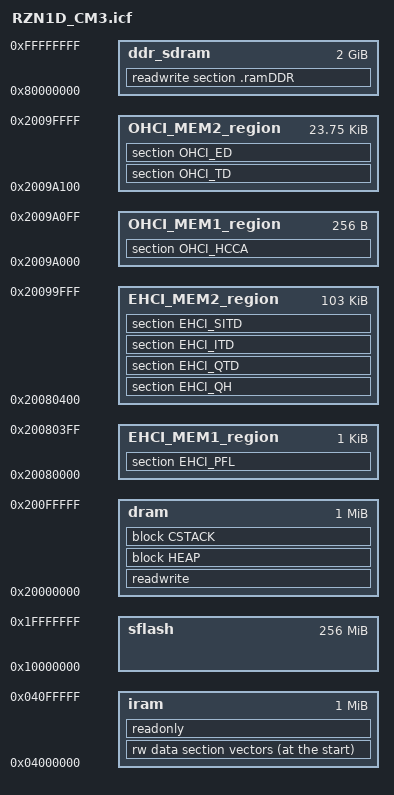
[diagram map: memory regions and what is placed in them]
define symbol __ICFEDIT_intvec_start__ = 0x04000000;
/*-Memory Regions-*/
define symbol __ICFEDIT_region_ROM_start__ = 0x04000000; 		/* Instruction RAM  */
define symbol __ICFEDIT_region_ROM_end__   = 0x040BFFFF;
define symbol __ICFEDIT_region_RAM_start__ = 0x20000000; 		/* Data RAM */
define symbol __ICFEDIT_region_RAM_end__   = 0x200FFFFF;

define symbol _region_EHCI_MEM1_start__  = 0x20080000;
define symbol _region_EHCI_MEM1_end__    = 0x200803FF;
define symbol _region_EHCI_MEM2_start__  = 0x20080400;
define symbol _region_EHCI_MEM2_end__    = 0x20099FFF;
define symbol _region_OHCI_MEM1_start__  = 0x2009A000;
define symbol _region_OHCI_MEM1_end__    = 0x2009A0FF;
define symbol _region_OHCI_MEM2_start__  = 0x2009A100;
define symbol _region_OHCI_MEM2_end__    = 0x2009FFFF;


/*-Sizes-*/
define symbol __ICFEDIT_size_cstack__ = 0x8000;
define symbol __ICFEDIT_size_heap__   = 0x800;

/*============================================================================*/
/* M E M O R Y   R E G I O N                                                  */
/*============================================================================*/
define memory mem with size = 4G;

define region iram      = mem:[from 0x04000000 size 1M];        /*!< Instruction RAM  */
define region sflash    = mem:[from 0x10000000 size 256M];      /*!< Serial Flash-ROM (accessed via QSPI)*/
define region dram      = mem:[from 0x20000000 size 1M];        /*!< Data RAM */
define region ddr_sdram = mem:[from 0x80000000 size 2G];        /*!< DDR SDRAM */

define region EHCI_MEM1_region = mem:[from _region_EHCI_MEM1_start__ to _region_EHCI_MEM1_end__];
define region EHCI_MEM2_region = mem:[from _region_EHCI_MEM2_start__ to _region_EHCI_MEM2_end__];
define region OHCI_MEM1_region = mem:[from _region_OHCI_MEM1_start__ to _region_OHCI_MEM1_end__];
define region OHCI_MEM2_region = mem:[from _region_OHCI_MEM2_start__ to _region_OHCI_MEM2_end__];


/*============================================================================*/
/* B L O C K   L A Y O U T                                                    */
/*============================================================================*/
define block CSTACK    with alignment = 8, size = __ICFEDIT_size_cstack__   { };
define block HEAP      with alignment = 8, size = __ICFEDIT_size_heap__     { };

initialize by copy { readwrite } except { rw data section vectors };
do not initialize  { section .noinit };

/*============================================================================*/
/* S E C T I O N   L A Y O U T                                                */
/*============================================================================*/
//---------------------------------
// Flash ROM
//---------------------------------

//---------------------------------
// Instruction RAM
//---------------------------------
place at start of iram { rw data section vectors };
place in          iram { readonly };

//---------------------------------
// Data RAM
//---------------------------------
place in EHCI_MEM1_region { section EHCI_PFL };
place in EHCI_MEM2_region { section EHCI_QH, section EHCI_QTD, section EHCI_ITD, section EHCI_SITD };
place in OHCI_MEM1_region { section OHCI_HCCA };
place in OHCI_MEM2_region { section OHCI_TD, section OHCI_ED };

place in dram { readwrite,
                block HEAP,
                block CSTACK
              };
              
place in ddr_sdram   {readwrite section .ramDDR};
